VERSION ""

NS_ :

BS_:
BU_: Inverter
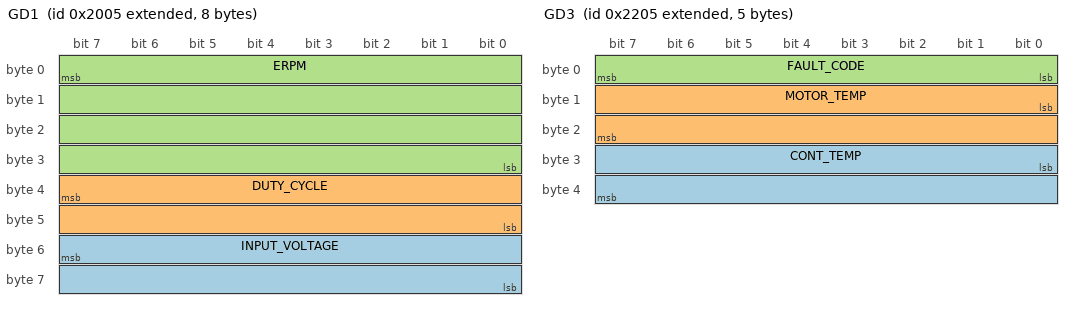
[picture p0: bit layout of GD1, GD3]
BO_ 2147491845 GD1: 8 Inverter
   SG_ INPUT_VOLTAGE : 55|16@0- (1,0) [-32768|32767] "V" Vector__XXX
   SG_ DUTY_CYCLE : 39|16@0- (10,0) [-32768|32767] "%" Vector__XXX
   SG_ ERPM : 7|32@0- (1,0) [-2147483648|2147483647] "ERPM" Vector__XXX

BO_ 2147492101 GD2: 4 Inverter
   SG_ ACI : 16|16@1- (10,0) [-32768|32767] "A" Vector__XXX
   SG_ DCI : 0|16@1- (10,0) [-32768|32767] "A" Vector__XXX

BO_ 2147492357 GD3: 5 Inverter
   SG_ CONT_TEMP : 24|16@1- (10,0) [-32768|32767] "C" Vector__XXX
   SG_ MOTOR_TEMP : 8|16@1+ (10,0) [-32768|32767] "C" Vector__XXX
   SG_ FAULT_CODE : 0|8@1+ (0,0) [0|0] "" Vector__XXX

BO_ 2147492613 GD4: 8 Inverter
   SG_ Id : 32|32@1+ (100,0) [-2147483648|2147483647] "A" Vector__XXX
   SG_ Iq : 0|32@1+ (100,0) [-2147483648|2147483647] "A" Vector__XXX

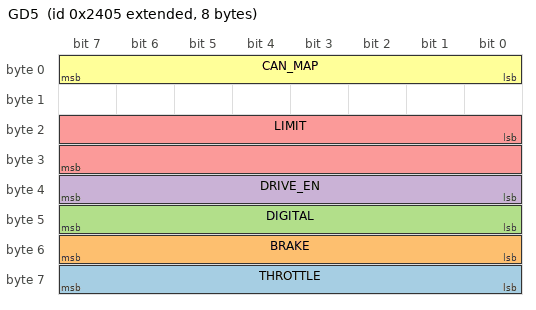
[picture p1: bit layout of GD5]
BO_ 2147492869 GD5: 8 Inverter
   SG_ THROTTLE : 56|8@1- (1,0) [-128|127] "%" Vector__XXX
   SG_ BRAKE : 48|8@1- (1,0) [-128|127] "%" Vector__XXX
   SG_ DIGITAL : 40|8@1+ (0,0) [0|0] "" Vector__XXX
   SG_ DRIVE_EN : 32|8@1+ (0,0) [0|0] "" Vector__XXX
   SG_ LIMIT : 16|16@1+ (0,0) [0|0] "" Vector__XXX
   SG_ CAN_MAP : 0|8@1+ (0,0) [0|0] "" Vector__XXX

CM_ BU_ Inverter "DTI HV-550";
BA_DEF_ BO_ "GenMsgBackgroundColor" STRING ;
BA_DEF_ BO_ "GenMsgForegroundColor" STRING ;
BA_DEF_ BO_ "filterlabeling" INT 0 0;
BA_DEF_DEF_ "GenMsgBackgroundColor" "#ffffff";
BA_DEF_DEF_ "GenMsgForegroundColor" "#232629";
BA_DEF_DEF_ "filterlabeling" 1;
BA_ "GenMsgForegroundColor" BO_ 2147491845 "#000000";
VAL_ 2147491845 ERPM 0 "";

CM_ BO_ 2147491845 "General Data 1";
CM_ BO_ 2147492101 "General Data 2";
CM_ BO_ 2147492357 "General Data 3";
CM_ BO_ 2147492613 "General Data 4";
CM_ BO_ 2147492869 "General Data 5";
